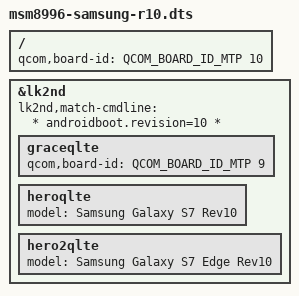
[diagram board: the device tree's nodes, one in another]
// SPDX-License-Identifier: BSD-3-Clause

#include "msm8996-samsung.dtsi"

/ {
	qcom,board-id = <QCOM_BOARD_ID_MTP 10>;
};

&lk2nd {
	lk2nd,match-cmdline = "* androidboot.revision=10 *";

	graceqlte {
		qcom,board-id = <QCOM_BOARD_ID_MTP 9>;
	};

	heroqlte {
		model = "Samsung Galaxy S7 Rev10";
	};

	hero2qlte {
		model = "Samsung Galaxy S7 Edge Rev10";
	};
};
